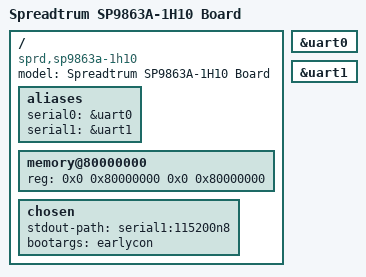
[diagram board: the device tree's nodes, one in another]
// SPDX-License-Identifier: GPL-2.0-only
/*
 * Unisoc SP9863A-1h10 boards DTS file
 *
 * Copyright (C) 2019, Unisoc Inc.
 */

/dts-v1/;

#include "sc9863a.dtsi"

/ {
	model = "Spreadtrum SP9863A-1H10 Board";

	compatible = "sprd,sp9863a-1h10", "sprd,sc9863a";

	aliases {
		serial0 = &uart0;
		serial1 = &uart1;
	};

	memory@80000000 {
		device_type = "memory";
		reg = <0x0 0x80000000 0x0 0x80000000>;
	};

	chosen {
		stdout-path = "serial1:115200n8";
		bootargs = "earlycon";
	};
};

&uart0 {
	status = "okay";
};

&uart1 {
	status = "okay";
};
